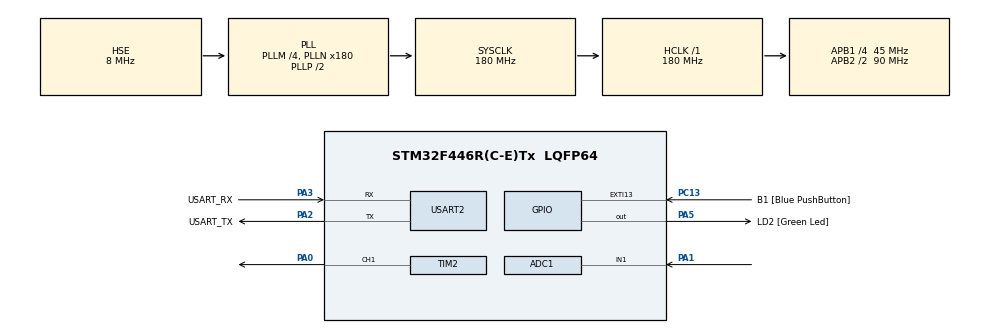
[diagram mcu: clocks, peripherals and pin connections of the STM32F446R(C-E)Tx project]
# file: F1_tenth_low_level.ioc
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ADC1.Channel-1\#ChannelRegularConversion=ADC_CHANNEL_1
ADC1.ContinuousConvMode=ENABLE
ADC1.DMAContinuousRequests=ENABLE
ADC1.NbrOfConversionFlag=1
ADC1.Rank-1\#ChannelRegularConversion=1
ADC1.SamplingTime-1\#ChannelRegularConversion=ADC_SAMPLETIME_3CYCLES
ADC1.master=1
Dma.ADC1.2.Direction=DMA_PERIPH_TO_MEMORY
Dma.ADC1.2.FIFOMode=DMA_FIFOMODE_DISABLE
Dma.ADC1.2.Instance=DMA2_Stream0
Dma.ADC1.2.MemDataAlignment=DMA_MDATAALIGN_WORD
Dma.ADC1.2.MemInc=DMA_MINC_ENABLE
Dma.ADC1.2.Mode=DMA_CIRCULAR
Dma.ADC1.2.PeriphDataAlignment=DMA_PDATAALIGN_WORD
Dma.ADC1.2.PeriphInc=DMA_PINC_DISABLE
Dma.ADC1.2.Priority=DMA_PRIORITY_HIGH
Dma.Request0=USART2_RX
Dma.Request1=USART2_TX
Dma.Request2=ADC1
Dma.USART2_RX.0.Direction=DMA_PERIPH_TO_MEMORY
Dma.USART2_RX.0.FIFOMode=DMA_FIFOMODE_DISABLE
Dma.USART2_RX.0.Instance=DMA1_Stream5
Dma.USART2_RX.0.MemDataAlignment=DMA_MDATAALIGN_BYTE
Dma.USART2_RX.0.MemInc=DMA_MINC_ENABLE
Dma.USART2_RX.0.Mode=DMA_CIRCULAR
Dma.USART2_RX.0.PeriphDataAlignment=DMA_PDATAALIGN_BYTE
Dma.USART2_RX.0.PeriphInc=DMA_PINC_DISABLE
Dma.USART2_RX.0.Priority=DMA_PRIORITY_VERY_HIGH
Dma.USART2_TX.1.Direction=DMA_MEMORY_TO_PERIPH
Dma.USART2_TX.1.FIFOMode=DMA_FIFOMODE_DISABLE
Dma.USART2_TX.1.Instance=DMA1_Stream6
Dma.USART2_TX.1.MemDataAlignment=DMA_MDATAALIGN_BYTE
Dma.USART2_TX.1.MemInc=DMA_MINC_ENABLE
Dma.USART2_TX.1.Mode=DMA_NORMAL
Dma.USART2_TX.1.PeriphDataAlignment=DMA_PDATAALIGN_BYTE
Dma.USART2_TX.1.PeriphInc=DMA_PINC_DISABLE
Dma.USART2_TX.1.Priority=DMA_PRIORITY_VERY_HIGH
FREERTOS.Tasks01=defaultTask,24,3000,StartDefaultTask,Default,NULL,Dynamic,NULL,NULL
Mcu.Family=STM32F4
Mcu.Name=STM32F446R(C-E)Tx
Mcu.Package=LQFP64
NVIC.DMA1_Stream5_IRQn=true\:5\:0\:false\:false\:true\:true\:false\:true\:true
NVIC.DMA1_Stream6_IRQn=true\:5\:0\:false\:false\:true\:true\:false\:true\:true
NVIC.DMA2_Stream0_IRQn=true\:5\:0\:false\:false\:true\:true\:false\:true\:true
NVIC.PriorityGroup=NVIC_PRIORITYGROUP_4
NVIC.TIM1_UP_TIM10_IRQn=true\:15\:0\:false\:false\:true\:false\:false\:true\:true
NVIC.TimeBase=TIM1_UP_TIM10_IRQn
NVIC.TimeBaseIP=TIM1
NVIC.USART2_IRQn=true\:5\:0\:false\:false\:true\:true\:true\:true\:true
PA0-WKUP.Signal=S_TIM2_CH1_ETR
PA1.Signal=ADCx_IN1
PA13.GPIO_Label=TMS
PA13.Mode=Serial_Wire
PA13.Signal=SYS_JTMS-SWDIO
PA14.GPIO_Label=TCK
PA14.Mode=Serial_Wire
PA14.Signal=SYS_JTCK-SWCLK
PA2.GPIO_Label=USART_TX
PA2.Mode=Asynchronous
PA2.Signal=USART2_TX
PA3.GPIO_Label=USART_RX
PA3.Mode=Asynchronous
PA3.Signal=USART2_RX
PA5.GPIO_Label=LD2 [Green Led]
PA5.Signal=GPIO_Output
PB3.GPIO_Label=SWO
PB3.Signal=SYS_JTDO-SWO
PC13.GPIO_Label=B1 [Blue PushButton]
PC13.GPIO_ModeDefaultEXTI=GPIO_MODE_IT_FALLING
PC13.Signal=GPXTI13
PC14-OSC32_IN.Mode=LSE-External-Oscillator
PC14-OSC32_IN.Signal=RCC_OSC32_IN
PC15-OSC32_OUT.Mode=LSE-External-Oscillator
PC15-OSC32_OUT.Signal=RCC_OSC32_OUT
PH0-OSC_IN.Mode=HSE-External-Oscillator
PH0-OSC_IN.Signal=RCC_OSC_IN
PH1-OSC_OUT.Mode=HSE-External-Oscillator
PH1-OSC_OUT.Signal=RCC_OSC_OUT
ProjectManager.HeapSize=0x200
ProjectManager.StackSize=0x400
ProjectManager.TargetToolchain=Makefile
RCC.48MHZClocksFreq_Value=84000000
RCC.AHBFreq_Value=180000000
RCC.APB1CLKDivider=RCC_HCLK_DIV4
RCC.APB1Freq_Value=45000000
RCC.APB1TimFreq_Value=90000000
RCC.APB2CLKDivider=RCC_HCLK_DIV2
RCC.APB2Freq_Value=90000000
RCC.APB2TimFreq_Value=180000000
RCC.CortexFreq_Value=180000000
RCC.FLatency-AdvancedSettings=FLASH_LATENCY_5
RCC.HCLKFreq_Value=180000000
RCC.HSE_VALUE=8000000
RCC.HSI_VALUE=16000000
RCC.PLLM=4
RCC.PLLN=180
RCC.PLLSourceVirtual=RCC_PLLSOURCE_HSE
RCC.SYSCLKFreq_VALUE=180000000
RCC.SYSCLKSource=RCC_SYSCLKSOURCE_PLLCLK
RCC.USBFreq_Value=180000000
RCC.VCOOutputFreq_Value=360000000
SH.ADCx_IN1.0=ADC1_IN1,IN1
SH.S_TIM2_CH1_ETR.0=TIM2_CH1,PWM Generation1 CH1
TIM2.Channel-PWM\ Generation1\ CH1=TIM_CHANNEL_1
TIM2.Period=19999
TIM2.Prescaler=89
TIM2.Pulse-PWM\ Generation1\ CH1=1500
USART2.VirtualMode=VM_ASYNC
VP_FREERTOS_VS_CMSIS_V2.Mode=CMSIS_V2
VP_SYS_VS_tim1.Mode=TIM1
VP_TIM2_VS_ClockSourceINT.Mode=Internal
board=NUCLEO-F446RE

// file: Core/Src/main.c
/* USER CODE BEGIN Header */
/**
  ******************************************************************************
  * @file           : main.c
  * @brief          : Main program body
  ******************************************************************************
  * @attention
  *
  * Copyright (c) 2025 STMicroelectronics.
  * All rights reserved.
  *
  * This software is licensed under terms that can be found in the LICENSE file
  * in the root directory of this software component.
  * If no LICENSE file comes with this software, it is provided AS-IS.
  *
  ******************************************************************************
  */
/* USER CODE END Header */
#include "main.h"
#include "cmsis_os.h"
#include "adc.h"
#include "dma.h"
#include "tim.h"
#include "usart.h"
#include "gpio.h"

/* USER CODE BEGIN Includes */
#include "stm32_f466xx_servo.h"
/* USER CODE END Includes */

void SystemClock_Config(void);
void MX_FREERTOS_Init(void);

int main(void)
{

  /* MCU Configuration--------------------------------------------------------*/

  /* Reset of all peripherals, Initializes the Flash interface and the Systick. */
  HAL_Init();

  /* Configure the system clock */
  SystemClock_Config();

  /* Initialize all configured peripherals */
  MX_GPIO_Init();
  MX_DMA_Init();
  MX_USART2_UART_Init();
  MX_ADC1_Init();
  MX_TIM2_Init();

  /* Init scheduler */
  osKernelInitialize();  /* Call init function for freertos objects (in cmsis_os2.c) */
  MX_FREERTOS_Init();

  /* Start scheduler */
  osKernelStart();

  /* We should never get here as control is now taken by the scheduler */

  /* Infinite loop */
  while (1)
  {

  }
}

void SystemClock_Config(void)
{
  RCC_OscInitTypeDef RCC_OscInitStruct = {0};
  RCC_ClkInitTypeDef RCC_ClkInitStruct = {0};

  /** Configure the main internal regulator output voltage
  */
  __HAL_RCC_PWR_CLK_ENABLE();
  __HAL_PWR_VOLTAGESCALING_CONFIG(PWR_REGULATOR_VOLTAGE_SCALE1);

  /** Initializes the RCC Oscillators according to the specified parameters
  * in the RCC_OscInitTypeDef structure.
  */
  RCC_OscInitStruct.OscillatorType = RCC_OSCILLATORTYPE_HSE;
  RCC_OscInitStruct.HSEState = RCC_HSE_ON;
  RCC_OscInitStruct.PLL.PLLState = RCC_PLL_ON;
  RCC_OscInitStruct.PLL.PLLSource = RCC_PLLSOURCE_HSE;
  RCC_OscInitStruct.PLL.PLLM = 4;
  RCC_OscInitStruct.PLL.PLLN = 180;
  RCC_OscInitStruct.PLL.PLLP = RCC_PLLP_DIV2;
  RCC_OscInitStruct.PLL.PLLQ = 2;
  RCC_OscInitStruct.PLL.PLLR = 2;
  if (HAL_RCC_OscConfig(&RCC_OscInitStruct) != HAL_OK)
  {
    Error_Handler();
  }

  /** Activate the Over-Drive mode
  */
  if (HAL_PWREx_EnableOverDrive() != HAL_OK)
  {
    Error_Handler();
  }

  /** Initializes the CPU, AHB and APB buses clocks
  */
  RCC_ClkInitStruct.ClockType = RCC_CLOCKTYPE_HCLK|RCC_CLOCKTYPE_SYSCLK
                              |RCC_CLOCKTYPE_PCLK1|RCC_CLOCKTYPE_PCLK2;
  RCC_ClkInitStruct.SYSCLKSource = RCC_SYSCLKSOURCE_PLLCLK;
  RCC_ClkInitStruct.AHBCLKDivider = RCC_SYSCLK_DIV1;
  RCC_ClkInitStruct.APB1CLKDivider = RCC_HCLK_DIV4;
  RCC_ClkInitStruct.APB2CLKDivider = RCC_HCLK_DIV2;

  if (HAL_RCC_ClockConfig(&RCC_ClkInitStruct, FLASH_LATENCY_5) != HAL_OK)
  {
    Error_Handler();
  }
}

void HAL_TIM_PeriodElapsedCallback(TIM_HandleTypeDef *htim)
{
  if (htim->Instance == TIM1)
  {
    HAL_IncTick();
  }
}

void Error_Handler(void)
{
  __disable_irq();
  while (1)
  {
  }
}

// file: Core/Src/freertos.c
/* USER CODE BEGIN Header */
/**
  ******************************************************************************
  * File Name          : freertos.c
  * Description        : Code for freertos applications
  ******************************************************************************
  * @attention
  *
  * Copyright (c) 2025 STMicroelectronics.
  * All rights reserved.
  *
  * This software is licensed under terms that can be found in the LICENSE file
  * in the root directory of this software component.
  * If no LICENSE file comes with this software, it is provided AS-IS.
  *
  ******************************************************************************
  */
/* USER CODE END Header */

#include "FreeRTOS.h"
#include "task.h"
#include "main.h"
#include "cmsis_os.h"

/* Definitions for defaultTask */
osThreadId_t defaultTaskHandle;
const osThreadAttr_t defaultTask_attributes = {
  .name = "defaultTask",
  .stack_size = 3000 * 4,
  .priority = (osPriority_t) osPriorityNormal,
};

void StartDefaultTask(void *argument);

void MX_FREERTOS_Init(void); /* (MISRA C 2004 rule 8.1) */

void MX_FREERTOS_Init(void) {

  /* Create the thread(s) */
  /* creation of defaultTask */
  defaultTaskHandle = osThreadNew(StartDefaultTask, NULL, &defaultTask_attributes);

}

void StartDefaultTask(void *argument)
{
  for(;;)
  {
    osDelay(1);
  }
}
